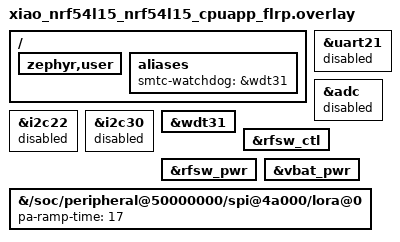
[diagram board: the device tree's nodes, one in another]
/*
 * Copyright (c) 2024 Semtech Corporation
 *
 * SPDX-License-Identifier: Apache-2.0
 */

/ {
	zephyr,user {
		/* PINS used for the HW modem sample. */
	};

	aliases {
		/* Host UART auto-selected from chosen zephyr,console (uart20 = USB serial). */
		smtc-watchdog = &wdt31;
	};
};

// Host link on the USB serial (uart20 = console), already enabled @115200 by the
// base board DTS. Just turn off the unused header UART.
&uart21 {
	status = "disabled";
};

&adc {
	status = "disabled";
};

&i2c22 {
	status = "disabled";
};

&i2c30 {
	status = "disabled";
};

&wdt31 {
	status = "okay";
};

// Override xiao_nrf54l15 default configuration for USP applications
// Disable boot-on for RF switch regulators to save power

&rfsw_ctl {
	/delete-property/ regulator-boot-on;
};

&rfsw_pwr {
	/delete-property/ regulator-boot-on;
};

&vbat_pwr {
	/delete-property/ regulator-boot-on;
};

// Set pa ramp time to 272us for this sample
&{/soc/peripheral@50000000/spi@4a000/lora@0} {
        pa-ramp-time = <17>; // 272us
};
